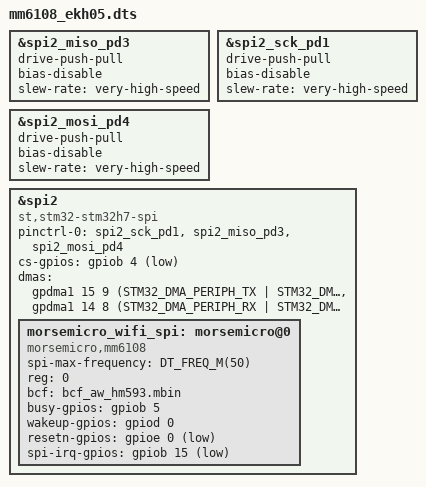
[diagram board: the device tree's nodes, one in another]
/*
 * Copyright 2025-2026 Morse Micro
 *
 * SPDX-License-Identifier: Apache-2.0
 */

/dts-v1/;
#include "mm6108_ekh05_common.dtsi"
#include <zephyr/dt-bindings/dma/stm32_dma.h>

/* MM Module SPI connecters */

&spi2_miso_pd3 {
	drive-push-pull;
	bias-disable;
	/delete-property/ bias-pull-down;
	slew-rate = "very-high-speed";
};

&spi2_sck_pd1 {
	drive-push-pull;
	bias-disable;
	/delete-property/ bias-pull-down;
	slew-rate = "very-high-speed";
};

&spi2_mosi_pd4 {
	drive-push-pull;
	bias-disable;
	/delete-property/ bias-pull-down;
	slew-rate = "very-high-speed";
};

&spi2 {
	compatible = "st,stm32-stm32h7-spi", "st,stm32-fifo-spi", "st,stm32-spi";
	status = "okay";
	pinctrl-0 = <&spi2_sck_pd1 &spi2_miso_pd3 &spi2_mosi_pd4>;
	pinctrl-names = "default";
	cs-gpios = <&gpiob 4 GPIO_ACTIVE_LOW>;

    //         channel slot channel-config (st,stm32-dma_v2.yaml)
    dmas = <&gpdma1 15 9 (STM32_DMA_PERIPH_TX | STM32_DMA_PRIORITY_VERY_HIGH)>,
           <&gpdma1 14 8 (STM32_DMA_PERIPH_RX | STM32_DMA_PRIORITY_VERY_HIGH)>;
    dma-names = "tx", "rx";

	morsemicro_wifi_spi: morsemicro@0 {
		status = "okay";
		compatible = "morsemicro,mm6108";
		spi-max-frequency = <DT_FREQ_M(50)>;
		reg = <0>;

		bcf = "bcf_aw_hm593.mbin";
		busy-gpios = <&gpiob 5 GPIO_ACTIVE_HIGH>;
		wakeup-gpios = <&gpiod 0 GPIO_ACTIVE_HIGH>;
		resetn-gpios = <&gpioe 0 GPIO_ACTIVE_LOW>;
		spi-irq-gpios = <&gpiob 15 GPIO_ACTIVE_LOW>;
	};
};
